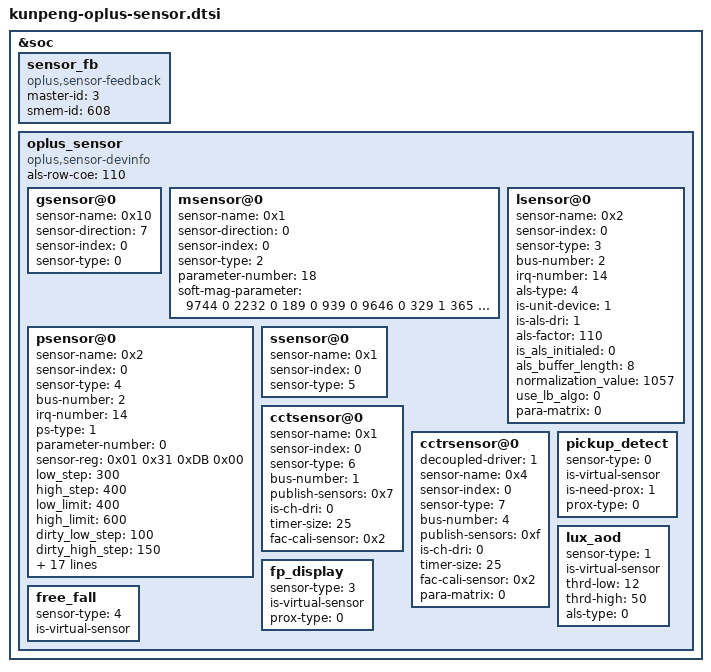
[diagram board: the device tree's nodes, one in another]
/**********************************************************************************
* Copyright (c)  2008-2021  Guangdong oplus Mobile Comm Corp., Ltd
* Description: oplus sensor dtsi
*
* Version: 1.0
* Date: 2021-07-12
*
* ------------------------------ Revision History: --------------------------------
* <version>           <date>                <author>                            <desc>
***********************************************************************************/
&soc {
	//#ifdef OPLUS_FEATURE_SENSOR_SMEM
	/*enum sensor_id { OPLUS_ACCEL,OPLUS_GYRO,OPLUS_MAG,OPLUS_LIGHT,OPLUS_PROXIMITY,OPLUS_SAR,OPLUS_CT,OPLUS_BAROMETER,SENSORS_NUM};*/
	sensor_fb: sensor_fb {
		compatible = "oplus,sensor-feedback";
		master-id  = <3>;
		smem-id    = <608>;
	};
	oplus_sensor {
		compatible = "oplus,sensor-devinfo";
		als-row-coe = <110>;
		/*enum {LSM6DSM = 0x01, BMI160 = 0x02, LSM6DS3 = 0x04, BMI260 = 0x08, LSM6DSO = 0x10};*/
		gsensor@0 {
			sensor-name = <0x10>;//LSM6DSO
			sensor-direction = <7>;
			sensor-index = <0>;//source num
			sensor-type = <0>;//OPLUS_ACCEL
		};
		/* enum {AKM0991X = 0x01, MMC5x3x = 0x02};*/
		msensor@0 {
			sensor-name = <0x1>;//AKM0991X
			sensor-direction = <0>;
			sensor-index = <0>;
			sensor-type = <2>;//OPLUS_MAG
			parameter-number= <18>;
			soft-mag-parameter = <9744 0 2232 0 189 0 939 0 9646 0 329 1 365 0 106 1 11525 0>;//e00 sign e01 sign...
		};
		/*enum {STK3A5X=0x01,TCS3701=0x02,TCS3408=0x04};*/
		lsensor@0 {
			sensor-name = <0x2>;//TCS3701
			sensor-index = <0>;
			sensor-type = <3>;//OPLUS_LIGHT
			bus-number = <2>;
			irq-number = <14>;
			als-type = <4>;//CCT_ALS
			is-unit-device = <1>;
			is-als-dri = <1>;
			als-factor = <110>;
			is_als_initialed = <0>;
			als_buffer_length = <8>;
			normalization_value = <1057>;
			use_lb_algo = <0>;
			para-matrix = <0>;
		};
		psensor@0 {
			sensor-name = <0x2>;//TCS3701
			sensor-index = <0>;
			sensor-type = <4>;//OPLUS_PROXIMITY
			bus-number = <2>;
			irq-number = <14>;
			ps-type = <1>;
			/*sensor-reg start*/
			parameter-number = <0>;
			sensor-reg = <0x01 0x31
						  0xDB 0x00>; //override special reg
			/*sensor-reg end*/
			low_step = <300>;
			high_step = <400>;
			low_limit = <400>;
			high_limit = <600>;
			dirty_low_step = <100>;
			dirty_high_step = <150>;
			ps_dirty_limit = <1020>;
			ps_ir_limit = <500>;
			ps_adjust_min = <0>;
			ps_adjust_max = <600>;
			sampling_count = <5>;
			step_max = <400>;
			step_min = <100>;
			step_div = <1500>;
			anti_shake_delta = <80>;
			dynamic_cali_max = <1024>;
			raw2offset_radio = <20800>;
			offset_max = <250>;
			offset_range_min = <0xFFFFFF01>;// -255
			offset_range_max = <255>;
			force_cali_limit = <2000>;
			cali_jitter_limit = <20>;
			cal_offset_margin = <80>;
		};
		/* enum {SX9324 = 0x01} */
		ssensor@0 {
			sensor-name = <0x1>;//SX9324
			sensor-index = <0>;
			sensor-type = <5>;//OPLUS_SAR
		};
		/* enum {tcs3408 = 0x01  stk37600 = 0x02  AS7352 = 0x04} */
		cctsensor@0 {
			sensor-name = <0x1>; //tcs3408
			sensor-index = <0>;
			sensor-type = <6>; //OPLUS_CCT
			bus-number = <1>;
			//feature
			publish-sensors = <0x7>; //bit[0] - als, bit[1] - rgb, bit[2] - flicker
			is-ch-dri = <0>;
			timer-size = <25>; //ms
			fac-cali-sensor = <0x2>; //0x1 - als, 0x2 - rgb, 0x4, flicker
		};
		cctrsensor@0 {
			decoupled-driver = <1>; //0 - tcs3408 driver; 1 - oplus_cct driver
			sensor-name = <0x4>; //AS7352
			sensor-index = <0>;
			sensor-type = <7>; //OPLUS_CCT_REAR
			bus-number = <4>;
			//feature
			publish-sensors = <0xf>; //bit[0] - als, bit[1] - rgb, bit[2] - flicker, bit[3] - spectral
			is-ch-dri = <0>;
			timer-size = <25>; //ms
			fac-cali-sensor = <0x2>; //0x1 - als, 0x2 - rgb, 0x4, flicker
			para-matrix = <0>;//0-default
		};
		/*virtual sensor
		enum sensor_algo_id {
			OPLUS_PICKUP_DETECT,
			OPLUS_LUX_AOD,
			OPLUS_TP_GESTURE,
			OPLUS_FP_DISPLAY,
			OPLUS_FREE_FALL,
			OPLUS_CAMERA_PROTECT,
			SENSOR_ALGO_NUM
		}*/
		pickup_detect {
			sensor-type = <0>;//OPLUS_PICKUP_DETECT
			is-virtual-sensor;
			is-need-prox = <1>;
			prox-type = <0>;
		};
		lux_aod {
			sensor-type = <1>; //OPLUS_LUX_AOD
			is-virtual-sensor;
			thrd-low = <12>;
			thrd-high = <50>;
			als-type = <0>;
		};
		fp_display {
			sensor-type = <3>;//OPLUS_FP_DISPLAY
			is-virtual-sensor;
			prox-type = <0>; // 0 - proximity; 1 - proximity_fake
		};
		free_fall {
			sensor-type = <4>;//OPLUS_FREE_FALL
			is-virtual-sensor;
		};
	};
	//#endif /*OPLUS_FEATURE_SENSOR_SMEM*/
};



